# AT32M416xx_v2 register map
Vendor: Keil; Series: AT32M416; File version: 1.0
CPU: CM4 r0p1, little endian, no MPU, FPU, 4 interrupt priority bits
Registers are 32-bit, read-write, reset 0x0 unless marked. A register's access mark holds for its fields unless they carry their own. Offsets are from the block's base; [hi:lo] are bit positions; {n}, {i} and the like mark numbered series.

## USART1 — Universal synchronous asynchronous receiver transmitter
Base 0x40011000
Same registers: USART2 0x40004400
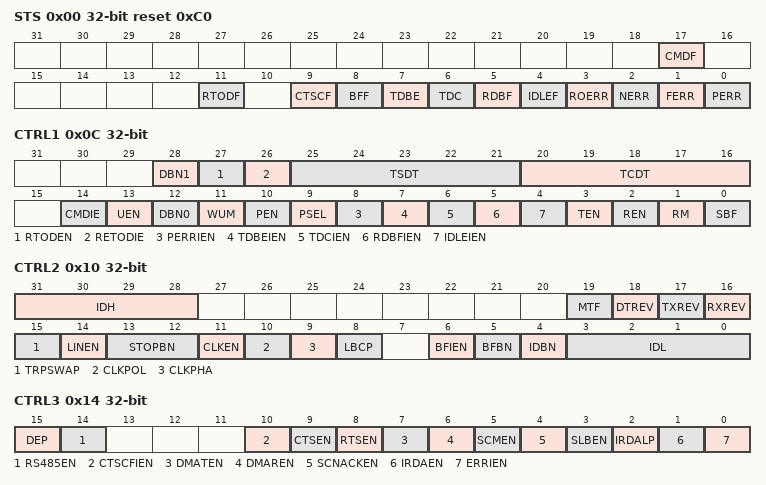
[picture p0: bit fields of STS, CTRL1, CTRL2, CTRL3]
0x00 STS reset 0xC0 — Status register
  [17] CMDF ro — Character match detect flag
  [11] RTODF ro — Receiver time out detection flag
  [9] CTSCF — CTS change flag
  [8] BFF — Break frame flag
  [7] TDBE ro — Transmit data buffer empty
  [6] TDC — Transmit data complete
  [5] RDBF — Receive data buffer full
  [4] IDLEF ro — IDLE flag
  [3] ROERR ro — Receiver overflow error
  [2] NERR ro — Noise error
  [1] FERR ro — Framing error
  [0] PERR ro — Parity error
0x04 DT — Data register
  [8:0] DT — Data value
0x08 BAUDR — Baud rate register
  [15:0] DIV — Division
0x0C CTRL1 — Control register 1
  [28] DBN1 — high bit for Data bit num
  [27] RTODEN — Receiver time out detection enable
  [26] RETODIE — Receiver time out detection interrupt enable
  [25:21] TSDT — transmit start delay time
  [20:16] TCDT — transmit complete delay time
  [14] CMDIE — Character match detection interrupt enable
  [13] UEN — USART enable
  [12] DBN0 — low bit for Data bit num
  [11] WUM — Wake up mode
  [10] PEN — Parity enable
  [9] PSEL — Parity selection
  [8] PERRIEN — PERR interrupt enable
  [7] TDBEIEN — TDBE interrupt enable
  [6] TDCIEN — TDC interrupt enable
  [5] RDBFIEN — RDBF interrupt enable
  [4] IDLEIEN — IDLE interrupt enable
  [3] TEN — Transmitter enable
  [2] REN — Receiver enable
  [1] RM — Receiver mute
  [0] SBF — Send break frame
0x10 CTRL2 — Control register 2
  [31:28] IDH — bit 7-4 for usart identification
  [19] MTF — MSB transmit first
  [18] DTREV — DT register polarity reverse
  [17] TXREV — TX polarity reverse
  [16] RXREV — RX polarity reverse
  [15] TRPSWAP — Transmit receive pin swap
  [14] LINEN — LIN mode enable
  [13:12] STOPBN — STOP bit num
  [11] CLKEN — Clock enable
  [10] CLKPOL — Clock polarity
  [9] CLKPHA — Clock phase
  [8] LBCP — Last bit clock pulse
  [6] BFIEN — Break frame interrupt enable
  [5] BFBN — Break frame bit num
  [4] IDBN — Identification bit num
  [3:0] IDL — bit 3-0 for usart identification
0x14 CTRL3 — Control register 3
  [15] DEP — DE polarity selection
  [14] RS485EN — RS485 enable
  [10] CTSCFIEN — CTSCF interrupt enable
  [9] CTSEN — CTS enable
  [8] RTSEN — RTS enable
  [7] DMATEN — DMA transmitter enable
  [6] DMAREN — DMA receiver enable
  [5] SCMEN — Smartcard mode enable
  [4] SCNACKEN — Smartcard NACK enable
  [3] SLBEN — Single line bidirectional half-duplex enable
  [2] IRDALP — IrDA low-power mode
  [1] IRDAEN — IrDA enable
  [0] ERRIEN — Error interrupt enable
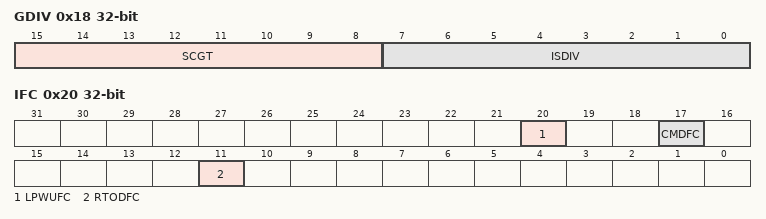
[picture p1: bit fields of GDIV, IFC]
0x18 GDIV — Guard time and division register
  [15:8] SCGT — Smart card guard time value
  [7:0] ISDIV — IrDA/smartcard division value
0x1C RTOV — Receiver time out value register
  [23:0] RTOV — Receiver time out value
0x20 IFC wo — Interrupt flag clear register
  [20] LPWUFC — Low power wake up flag clear
  [17] CMDFC — Character match flag clear
  [11] RTODFC — Receiver time out detection flag clear

## ADCCOM — ADC common area
Base 0x40012300
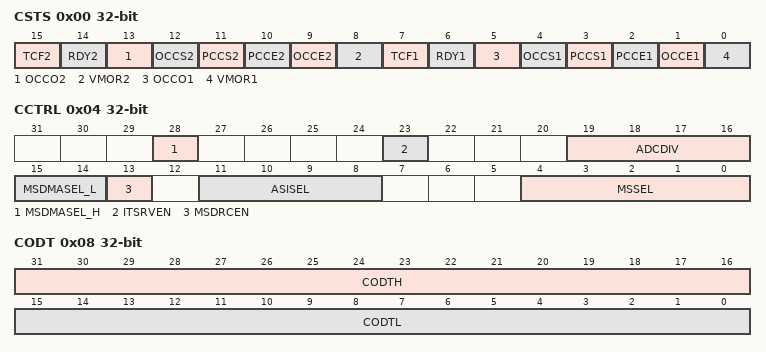
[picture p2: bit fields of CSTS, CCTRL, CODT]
0x00 CSTS ro — Common status register
  [15] TCF2 — Trigger convert fail flag of ADC2
  [14] RDY2 — ADC ready to conversion flag of ADC2
  [13] OCCO2 — Ordinary channel conversion overflow flag of ADC2
  [12] OCCS2 — Ordinary channel conversion start flag of ADC2
  [11] PCCS2 — Preempted channel conversion start flag of ADC2
  [10] PCCE2 — Preempted channels conversion end flag of ADC2
  [9] OCCE2 — Ordinary channels conversion end flag of ADC2
  [8] VMOR2 — Voltage monitoring out of range flag of ADC2
  [7] TCF1 — Trigger convert fail flag of ADC1
  [6] RDY1 — ADC ready to conversion flag of ADC1
  [5] OCCO1 — Ordinary channel conversion overflow flag of ADC1
  [4] OCCS1 — Ordinary channel conversion start flag of ADC1
  [3] PCCS1 — Preempted channel conversion start flag of ADC1
  [2] PCCE1 — Preempted channels conversion end flag of ADC1
  [1] OCCE1 — Ordinary channels conversion end flag of ADC1
  [0] VMOR1 — Voltage monitoring out of range flag of ADC1
0x04 CCTRL — Common control register
  [28] MSDMASEL_H — High bit of ordinary channel DMA transfer mode select for master slave mode
  [23] ITSRVEN — Internal temperature sensor and VINTRV enable
  [19:16] ADCDIV — ADC division
  [15:14] MSDMASEL_L — Low bit of ordinary channel DMA transfer mode select for master slave mode
  [13] MSDRCEN — Ordinary channel DMA request continuation enable for master slave mode
  [11:8] ASISEL — Adjacent ADC sampling interval select for ordinary shifting mode
  [4:0] MSSEL — Master slave mode select
0x08 CODT ro — Common Ordinary data register
  [31:16] CODTH — Ordinary conversion high halfword data for master slave mode
  [15:0] CODTL — Ordinary conversion low halfword data for master slave mode
{0xC+4i} ADC1_ODT{i} ro (i=1..10) — ADC1 Ordinary data register {i}
  [15:0] ODT{i} — Conversion data of ordinary channel
{0xC+4i} ADC1_ODT{i} ro (i=11..13) — ADC1 Ordinary data register 1
  [15:0] ODT{i} — Conversion data of ordinary channel
{0xC+4i} ADC1_ODT{i} ro (i=14..16) — ADC1 Ordinary data register {i}
  [15:0] ODT{i} — Conversion data of ordinary channel
{0x4C+4i} ADC2_ODT{i} ro (i=1..10) — ADC2 Ordinary data register {i}
  [15:0] ODT{i} — Conversion data of ordinary channel
{0x4C+4i} ADC2_ODT{i} ro (i=11..13) — ADC2 Ordinary data register 1
  [15:0] ODT{i} — Conversion data of ordinary channel
{0x4C+4i} ADC2_ODT{i} ro (i=14..16) — ADC2 Ordinary data register {i}
  [15:0] ODT{i} — Conversion data of ordinary channel

## Notices in the file
Copyright (C) 2012-2014 ARM Limited. All rights reserved.
Purpose: System Viewer Description (SVD) Example (Schema Version 1.1)
This is a description of a none-existent and incomplete device
for demonstration purposes only.
Redistribution and use in source and binary forms, with or without
modification, are permitted provided that the following conditions are met:
- Redistributions of source code must retain the above copyright
notice, this list of conditions and the following disclaimer.
- Redistributions in binary form must reproduce the above copyright
notice, this list of conditions and the following disclaimer in the
documentation and/or other materials provided with the distribution.
- Neither the name of ARM nor the names of its contributors may be used
to endorse or promote products derived from this software without
specific prior written permission.
THIS SOFTWARE IS PROVIDED BY THE COPYRIGHT HOLDERS AND CONTRIBUTORS "AS IS"
AND ANY EXPRESS OR IMPLIED WARRANTIES, INCLUDING, BUT NOT LIMITED TO, THE
IMPLIED WARRANTIES OF MERCHANTABILITY AND FITNESS FOR A PARTICULAR PURPOSE
ARE DISCLAIMED. IN NO EVENT SHALL COPYRIGHT HOLDERS AND CONTRIBUTORS BE
LIABLE FOR ANY DIRECT, INDIRECT, INCIDENTAL, SPECIAL, EXEMPLARY, OR
CONSEQUENTIAL DAMAGES (INCLUDING, BUT NOT LIMITED TO, PROCUREMENT OF
SUBSTITUTE GOODS OR SERVICES; LOSS OF USE, DATA, OR PROFITS; OR BUSINESS
INTERRUPTION) HOWEVER CAUSED AND ON ANY THEORY OF LIABILITY, WHETHER IN
CONTRACT, STRICT LIABILITY, OR TORT (INCLUDING NEGLIGENCE OR OTHERWISE)
ARISING IN ANY WAY OUT OF THE USE OF THIS SOFTWARE, EVEN IF ADVISED OF THE
POSSIBILITY OF SUCH DAMAGE.
